# rCSL_upp_001 register map
Vendor: Texas Instruments
Peripheral module from a debugger description file (folder OMAPL138_C6748).
Registers are 32-bit, access not given, reset 0x0 unless marked. A register's access mark holds for its fields unless they carry their own. Offsets are as the file gives them; lines under a group give offsets from that group; [hi:lo] are bit positions; {n}, {i} and the like mark numbered series; 'fields as' and 'values as' point back to an identical list; <NAME> marks a mode.

## UPP — Universal Parallel Port
0x00 UPPID ro reset 0x44230100 — Peripheral Identification Register
  [31:0] REVID — Peripheral identification number
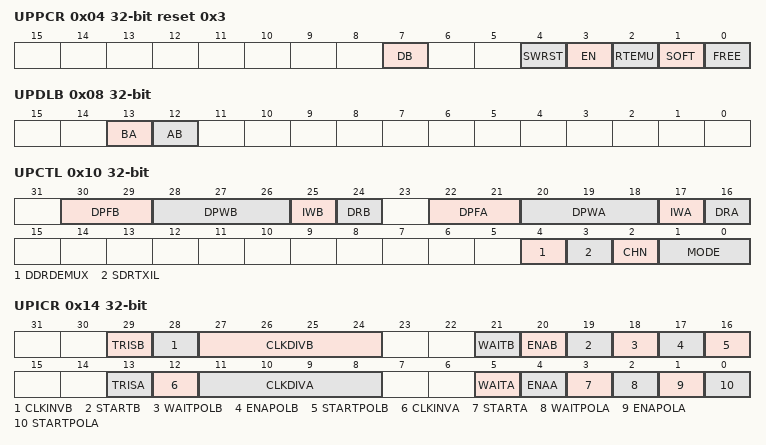
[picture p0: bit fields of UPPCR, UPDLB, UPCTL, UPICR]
0x04 UPPCR reset 0x3 — Peripheral Control Register
  [7] DB ro — DMA Burst Status. Reports whether internal DMA is currently active.
    0=Idle (Internal DMA is idle); 1=Active (Interna DMA is active)
  [4] SWRST rw — Software Reset Control. Assert to clear internal state machines and halt peripheral.
    0=Running (Peripheral not in reset); 1=Reset (Peripheral is in reset)
  [3] EN rw — Peripheral Enable Control
    0=Disable peripheral; 1=Enable peripheral
  [2] RTEMU rw — Real-time Emulation Control
    0=Disable (Real-time emulation disabled); 1=Enable (Real-time emulation enabled)
  [1] SOFT rw — Soft Stop Control
    0=Disable soft stop; 1=Enable soft stop
  [0] FREE rw — Free Run Control
    0=Disable free run; 1=Enable free run
0x08 UPDLB — Controls digital loopback functionality
  [13] BA rw — B to A Loopback Control
    0=Disable B to A digital loopback; 1=Enable B to A digital loopback
  [12] AB rw — A to B Loopback Control
    0=Disable A to B digital loopback; 1=Enable A to B digital loopback
0x10 UPCTL — Configures the uPP interface channels
  [30:29] DPFB rw — Channel B Data Packing Format
    0=RJZE (Right justify, zero extend); 1=RJSE (Right justify, sign extend); 2=LJZF (Left justify, zero fill)
  [28:26] DPWB rw — Channel B Data Width
    0=Full (Use full data bus); {v}={v+8}-bit format (v=1..7)
  [25] IWB rw — Channel B Interface Width
    0=8-bit interface; 1=16-bit interface
  [24] DRB rw — Channel B Data Rate
    0=Single data rate; 1=Double data rate
  [22:21] DPFA rw — Channel A Data Packing Format
    values as DPFB
  [20:18] DPWA rw — Channel A Data Width
    0=Full (Use full data bus); {v}={v+8}-bit format (v=1..7)
  [17] IWA rw — Channel A Interface Width
    0=8-bit interface; 1=16-bit interface
  [16] DRA rw — Channel A Data Rate
    0=Single data rate; 1=Double data rate
  [4] DDRDEMUX rw — Double Data Rate Interleave Control
    0=Disable Interleave (DDR only); 1=Enable Interleave (DDR only)
  [3] SDRTXIL rw — Single Data Rate Transmit Interleave Control
    0=Disable Interleave (SDR transmit only); 1=Enable Interleave (SDR transmit only)
  [2] CHN rw — Interface Channel Count
    0=One (One channel mode); 1=Two (Two channel mode)
  [1:0] MODE rw — Operating Mode Control
    0=Receive (All receive mode); 1=Transmit (All transmit mode); 2=Duplex0 (Duplex mode 0: channel A receives and channel B transmits); 3=Duplex1 (Duplex mode 1: channel A transmits and channel B receives)
0x14 UPICR — Configures signal use and polarity
  [29] TRISB rw — Channel B High Impedance
    0=Disable (Drive value from UPIVR when idle in transmit mode); 1=Enable (Set data pins to high impedance state when idle in transmit mode)
  [28] CLKINVB rw — Channel B Clock Inversion
    0=Normal (Do not invert clock signal); 1=Invert clock signal
  [27:24] CLKDIVB rw — Channel B Clock Divisor
  [21] WAITB rw — Channel B WAIT Signal Enable
    0=Disable (Ignore WAIT signal in transmit mode); 1=Enable (Honor WAIT signal in transmit mode)
  [20] ENAB rw — Channel B ENABLE Signal Enable
    0=Disable (Ignore ENABLE signal in receive mode); 1=Enable (Honor ENABLE signal in receive mode)
  [19] STARTB rw — Channel B START Signal Enable
    0=Disable (Ignore START signal in receive mode); 1=Enable (Honor START signal in receive mode)
  [18] WAITPOLB rw — Channel B WAIT Signal Polarity
    0=Normal (Do not invert WAIT signal); 1=Invert WAIT signal
  [17] ENAPOLB rw — Channel B ENABLE Signal Polarity
    0=Normal (Do not invert ENABLE signal); 1=Invert ENABLE signal
  [16] STARTPOLB rw — Channel B START Signal Polarity
    0=Normal (Do not invert START signal); 1=Invert START signal
  [13] TRISA rw — Channel A High Impedance
    values as TRISB
  [12] CLKINVA rw — Channel A Clock Inversion
    0=Normal (Do not invert clock signal); 1=Invert clock signal
  [11:8] CLKDIVA rw — Channel A Clock Divisor
  [5] WAITA rw — Channel A WAIT Signal Enable
    values as WAITB
  [4] ENAA rw — Channel A ENABLE Signal Enable
    values as ENAB
  [3] STARTA rw — Channel A START Signal Enable
    values as STARTB
  [2] WAITPOLA rw — Channel A WAIT Signal Polarity
    0=Normal (Do not invert WAIT signal); 1=Invert WAIT signal
  [1] ENAPOLA rw — Channel A ENABLE Signal Polarity
    values as ENAPOLB
  [0] STARTPOLA rw — Channel A START Signal Polarity
    0=Normal (Do not invert START signal); 1=Invert START signal
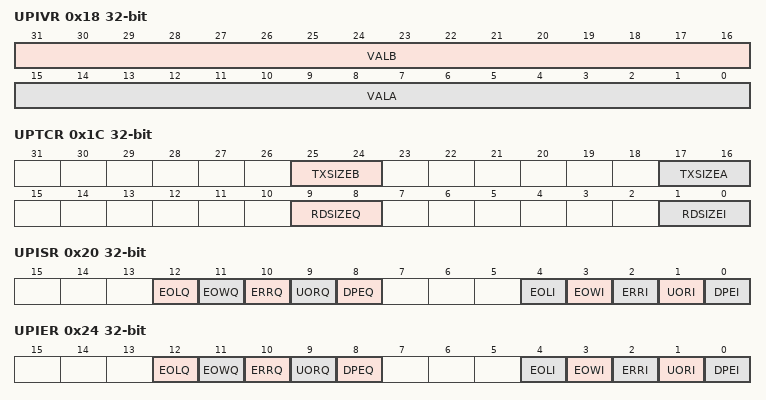
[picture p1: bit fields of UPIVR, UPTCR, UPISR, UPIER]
0x18 UPIVR rw — Configures the value to drive on each channel when idle in transmit mode
  [31:16] VALB — Channel B Idle Value
  [15:0] VALA — Channel A Idle Value
0x1C UPTCR — Configures the transmit threshold and DMA read burst for each channel
  [all] fields
    0=64B (64 bytes); 1=128B (128 bytes); 3=256B (256 bytes)
  [25:24] TXSIZEB rw — Channel B Transmit Threshold
  [17:16] TXSIZEA rw — Channel A Transmit Threshold
  [9:8] RDSIZEQ rw — DMA Channel Q Read Burst
  [1:0] RDSIZEI rw — DMA Channel I Read Burst
0x20 UPISR — Reports unfiltered interrupt event status
  [all] fields
    0=False (No interrupt event); 1=True (Interrupt event)
  [12] EOLQ rw — DMA Channel Q End of Line
  [11] EOWQ rw — DMA Channel Q End of Window
  [10] ERRQ rw — DMA Channel Q Internal Error
  [9] UORQ rw — DMA Channel Q Underrun or Overflow
  [8] DPEQ rw — DMA Channel Q Programming Error
  [4] EOLI rw — DMA Channel I End of Line
  [3] EOWI rw — DMA Channel I End of Window
  [2] ERRI rw — DMA Channel I Internal Error
  [1] UORI rw — DMA Channel I Underrun or Overflow
  [0] DPEI rw — DMA Channel I Programming Error
0x24 UPIER — Reports filtered interrupt event status
  fields as UPISR
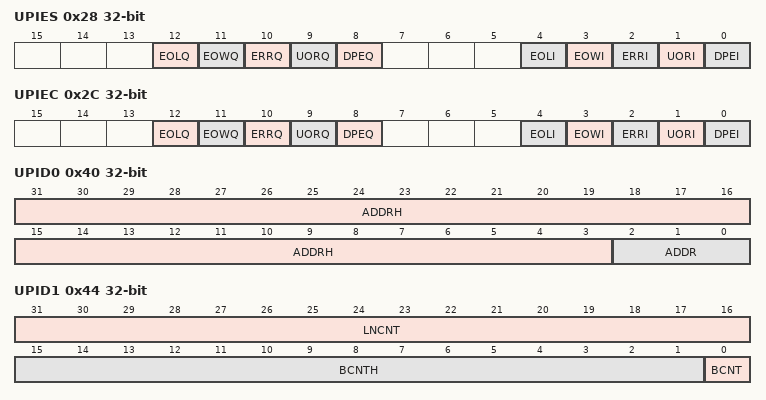
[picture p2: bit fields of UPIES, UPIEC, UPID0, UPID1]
0x28 UPIES — Enables interrupt generation for DMA channel events. Write 1 to enable. Write 0 has no effect.
  [all] fields
    0=Disabled (Interrupt disabled (read only)); 1=Set (Enable interrupt generation)
  [12] EOLQ rw — DMA Channel Q End of Line
  [11] EOWQ rw — DMA Channel Q End of Window
  [10] ERRQ rw — DMA Channel Q Internal Error
  [9] UORQ rw — DMA Channel Q Underrun or Overflow
  [8] DPEQ rw — DMA Channel Q Programming Error
  [4] EOLI rw — DMA Channel I End of Line
  [3] EOWI rw — DMA Channel I End of Window
  [2] ERRI rw — DMA Channel I Internal Error
  [1] UORI rw — DMA Channel I Underrun or Overflow
  [0] DPEI rw — DMA Channel I Programming Error
0x2C UPIEC — Disables interrupt generation for DMA channel events. Write 1 to disable. Write 0 has no effect.
  [all] fields
    0=Disabled (Interrupt disabled (read only)); 1=Clear interrupt generation
  [12] EOLQ rw — DMA Channel Q End of Line
  [11] EOWQ rw — DMA Channel Q End of Window
  [10] ERRQ rw — DMA Channel Q Internal Error
  [9] UORQ rw — DMA Channel Q Underrun or Overflow
  [8] DPEQ rw — DMA Channel Q Programming Error
  [4] EOLI rw — DMA Channel I End of Line
  [3] EOWI rw — DMA Channel I End of Window
  [2] ERRI rw — DMA Channel I Internal Error
  [1] UORI rw — DMA Channel I Underrun or Overflow
  [0] DPEI rw — DMA Channel I Programming Error
0x30 UPEOI — End of Interrupt Register
  [7:0] EOI rw — End of Interrupt Vector
    0=Done
0x40 UPID0 access per field — DMA Channel I Descriptor 0 Register
  [31:3] ADDRH rw — Window Address MSBs
  [2:0] ADDR ro — Window Address LSBs
0x44 UPID1 access per field — DMA Channel I Descriptor 1 Register
  [31:16] LNCNT rw — Line Count per Window
  [15:1] BCNTH rw — Byte Count per Line MSBs
  [0] BCNT ro — Byte Count per Line LSBs
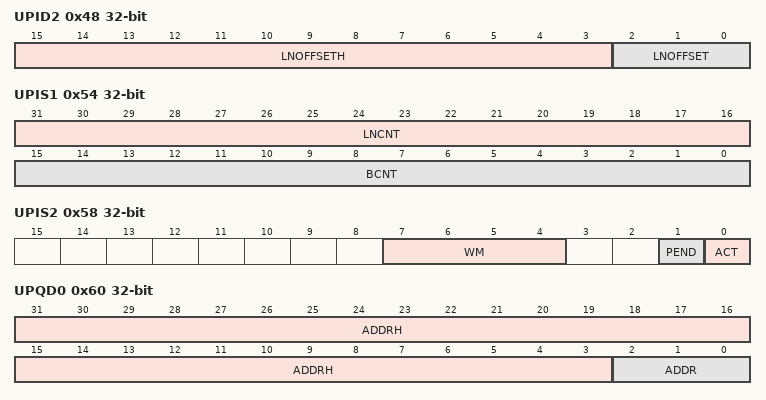
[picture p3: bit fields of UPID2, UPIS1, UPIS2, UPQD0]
0x48 UPID2 — DMA Channel I Descriptor 2 Register
  [15:3] LNOFFSETH rw — Line offset Address MSBs
  [2:0] LNOFFSET ro — Line offset Address LSBs
0x50 UPIS0 ro — DMA Channel I Status 0 Register
  [31:0] ADDR — Current Address of DMA Transfer
0x54 UPIS1 ro — DMA Channel I Status 1 Register
  [31:16] LNCNT — Current Line Number of DMA Transfer
  [15:0] BCNT — Current Byte Number Within Line of DMA Transfer
0x58 UPIS2 — DMA Channel I Status 2 Register
  [7:4] WM
  [1] PEND ro — DMA Transfer Pending
    0=False (No DMA Transfers Pending); 1=True (DMA Transfer Pending)
  [0] ACT ro — DMA Channel Active
    0=False (DMA Inactive); 1=True (DMA Active)
0x60 UPQD0 access per field — DMA Channel Q Descriptor 0 Register
  fields as UPID0
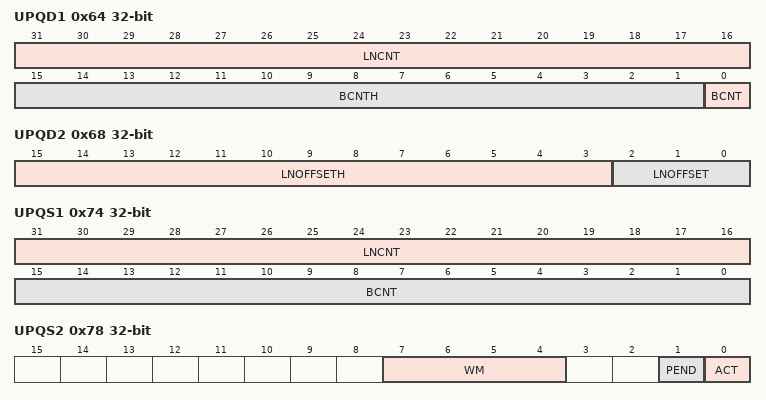
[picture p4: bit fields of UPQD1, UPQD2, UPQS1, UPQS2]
0x64 UPQD1 access per field — DMA Channel Q Descriptor 1 Register
  fields as UPID1
0x68 UPQD2 — DMA Channel Q Descriptor 2 Register
  fields as UPID2
0x70 UPQS0 ro — DMA Channel Q Status 0 Register
  [31:0] ADDR — Current Address of DMA Transfer
0x74 UPQS1 ro — DMA Channel Q Status 1 Register
  fields as UPIS1
0x78 UPQS2 — DMA Channel Q Status 2 Register
  fields as UPIS2
